# HS_I2C3 register map
Vendor: Texas Instruments
Peripheral module from a debugger description file (folder omap36xx).
Registers are 16-bit, read-write, reset 0x0 unless marked. A register's access mark holds for its fields unless they carry their own. Offsets are as the file gives them; lines under a group give offsets from that group; [hi:lo] are bit positions; {n}, {i} and the like mark numbered series; 'fields as' and 'values as' point back to an identical list; <NAME> marks a mode.

## HS_I2C3
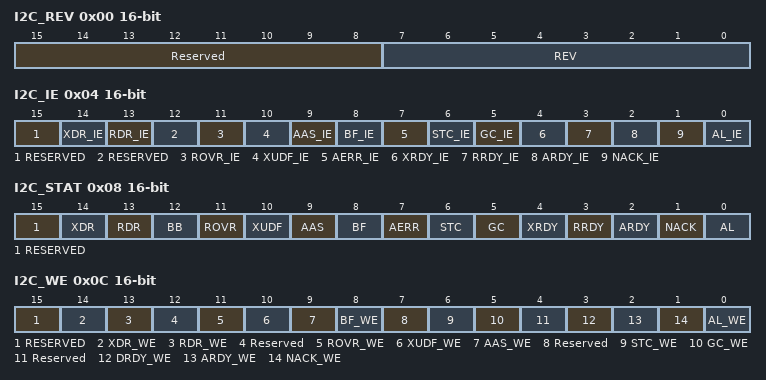
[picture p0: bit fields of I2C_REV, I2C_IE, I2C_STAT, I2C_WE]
0x00 I2C_REV ro (reset mask 0xFF00) — IP Revision Identifier (X.Y.R)Used by software to track features, bugs, and compatibility
  [15:8] Reserved — Read returns 0.
  [7:0] REV — IP revision[7:4] Major revision[3:0] Minor revisionExamples: 0x30 for 3.0, 0x31 for 3.1
0x04 I2C_IE — I2C interrupt enable register. This register contains the interrupt enable bits.
  [15] RESERVED — Write 0s for future compatibility. Read returns 0.
  [14] XDR_IE — Transmit Draining interrupt enable. Mask or unmask the interrupt signaled by the bit inI2C_STAT[XDR].
    0=Transmit Draining interrupt disabled; 1=Transmit Draining interrupt enabled
  [13] RDR_IE — Receive Draining interrupt enable. Mask or unmask the interrupt signaled by the bit inI2C_STAT[RDR].
    0=Receive Draining interrupt disabled; 1=Receive Draining interrupt enabled
  [12] RESERVED — Write 0s for future compatibility. Read returns 0.
  [11] ROVR_IE — Receive overrun enable set.
    0=Receive overrun interrupt disabled; 1=Receive Draining interrupt enabled
  [10] XUDF_IE — Transmit underflow enable set.
    0=Transmit underflow interrupt disabled; 1=Transmit underflow interrupt enabled
  [9] AAS_IE — Addressed as Slave interrupt enable. Mask or unmask the interrupt signaled by the bit inI2C_STAT[AAS].
    0=Addressed as Slave interrupt disabled; 1=Addressed as Slave interrupt enabled
  [8] BF_IE — Bus Free interrupt enable. Mask or unmask the interrupt signaled by the bit inI2C_STAT[BF].
    0=Bus Free interrupt disabled; 1=Bus Free interrupt enabled
  [7] AERR_IE — Access Error interrupt enable. Mask or unmask the interrupt signaled by the bit inI2C_STAT[AERR].
    0=Access Error interrupt disabled; 1=Access Error interrupt enabled
  [6] STC_IE — Start Condition interrupt enable. Mask or unmask the interrupt signaled by the bit inI2C_STAT[STC].
    0=Start Condition interrupt disabled; 1=Start Condition interrupt enabled
  [5] GC_IE — General Call interrupt enable. Mask or unmask the interrupt signaled by the bit inI2C_STAT[GC].
    0=General Call interrupt disabled; 1=General Call interrupt enabled
  [4] XRDY_IE — Transmit data ready interrupt enable. Mask or unmask the interrupt signaled by bit inI2C_STAT[XRDY]
    0=Transmit Data Ready interrupt disabled; 1=Transmit Data Ready interrupt enabled
  [3] RRDY_IE — Receive Data Ready interrupt enable. Mask or unmask the interrupt signaled by the bit inI2C_STAT[RRDY].
    0=Receive Data Ready interrupt disabled; 1=Receive Data Ready interrupt enabled
  [2] ARDY_IE — Register Access Ready interrupt enable. Mask or unmask the interrupt signaled by the bit inI2C_STAT[ARDY].
    0=Register Access Ready interrupt disabled; 1=Register Access Ready interrupt enabled
  [1] NACK_IE — No Acknowledgment interrupt enable. Mask or unmask the interrupt signaled by the bit inI2C_STAT[NACK].
    0=No Acknowledge interrupt disabled; 1=No Acknowledge Ready interrupt enabled
  [0] AL_IE — Arbitration Lost interrupt enable. Mask or unmask the interrupt signaled by the bit inI2C_STAT[AL].
    0=Arbitration Lost interrupt disabled; 1=Arbitration Lost interrupt enabled
0x08 I2C_STAT access per field — I2C status register. This register provides specific status information about the module, including interrupt status information
  [15] RESERVED rw — Write 0s for future compatibility. Read returns 0.
  [14] XDR rw — Transmit Draining IRQ status
    0=XDR_0_r (Transmit draining inactive); 1=XDR_1_r (Transmit draining active); 0=XDR_0_w (No effect); 1=XDR_1_w (Clear this bit to 0)
  [13] RDR rw — Receive Draining IRQ status
    0=RDR_0_r (Receive draining inactive); 1=RDR_1_r (Receive draining active); 0=RDR_0_w (No effect); 1=RDR_1_w (Clear this bit to 0)
  [12] BB ro — Bus busy status. Read-only bit. Writing this bit does not affect the read value.
    0=BB_0_r (Bus is free.); 1=BB_1_r (Bus is occupied.)
  [11] ROVR rw — Receive overrun status. Read-only bit. Writing this bit does not affect the read value.
    0=ROVR_0_r (Normal operation); 1=ROVR_1_r (Receiver overrun); 0=ROVR_0_w (No effect); 1=ROVR_1_w (Clear this bit to 0)
  [10] XUDF rw — Transmit underflow status. Read-only bit. Writing this bit does not affect the read value.
    0=XUDF_0_r (Normal operation); 1=XUDF_1_r (Transmit underflow); 0=XUDF_0_w (No effect); 1=XUDF_1_w (Clear this bit to 0)
  [9] AAS rw — Address recognized as slave IRQ status
    0=AAS_0_r (No action); 1=AAS_1_r (Address recognized); 0=AAS_0_w (No effect); 1=AAS_1_w (Clear this bit to 0.)
  [8] BF rw — Bus Free IRQ status
    0=BF_0_r (No action); 1=BF_1_r (Bus free); 0=BF_0_w (No effect); 1=BF_1_w (Clear this bit to 0.)
  [7] AERR rw — Access Error IRQ status
    0=AERR_0_r (No action); 1=AERR_1_r (Access error); 0=AERR_0_w (No effect); 1=AERR_1_w (Clear this bit to 0.)
  [6] STC rw — Start Condition IRQ status
    0=STC_0_r (No action); 1=STC_1_r (Start condition detected); 0=STC_0_w (No effect); 1=STC_1_w (Clear this bit to 0.)
  [5] GC rw — General Call IRQ status. Set to 1 when general call address detected. Interrupt signaled to MPU subsystem
    0=GC_0_r (No general call detected); 1=GC_1_r (General call address detected); 0=GC_0_w (No effect); 1=GC_1_w (Clear this bit to 0.)
  [4] XRDY rw — Transmit Data Ready IRQ status. Set to 1 in transmit mode when new data is requested for transmission. When this bit is set to 1, an interrupt is signaled to MPU subsystem
    0=XRDY_0_r (No transmit data is requested for transmission); 1=XRDY_1_r (Transmit data is requested for transmission); 0=XRDY_0_w (No effect); 1=XRDY_1_w (Clear this bit to 0.)
  [3] RRDY rw — Receive Data Ready IRQ status. Set to 1 when in receive mode, causing new data to be able to be read. When this bit is set to 1, an interrupt is signaled to MPU subsystem.
    0=RRDY_0_r (No data available); 1=RRDY_1_r (Receive data available); 0=RRDY_0_w (No effect); 1=RRDY_1_w (Clear this bit to 0.)
  [2] ARDY rw — Register Access Ready IRQ status. Setting this bit to 1 indicates that previous access has been performed and registers are ready to be accessed again. An interrupt is signaled to MPU subsystem.
    0=ARDY_0_r (Module busy); 1=ARDY_1_r (Access ready); 0=ARDY_0_w (No effect); 1=ARDY_1_w (Clear this bit to 0.)
  [1] NACK rw — No Acknowledgment IRQ status. This bit is set when No Acknowledgment has been received. An interrupt is signaled to MPU subsystem.In master mode, the transfer is automatically ended by generating a stop condition on the bus. The I2Ci.I2C_CON[1] STP, I2Ci.I2C_CON[10] MST and I2Ci.I2C_CON[9] TRX bits are automatically cleared to 0 (slave receiver mode). TX and RX FIFOs must be cleared (I2Ci.I2C_BUF[6] TXFIFO_CLR and I2Ci.I2C_BUF[14] RXFIFO_CLR bits set to 1).
    0=NACK_0_r (Normal operation); 1=NACK_1_r (No Acknowledge detected); 0=NACK_0_w (No effect); 1=NACK_1_w (Clear this bit to 0.)
  [0] AL rw — Arbitration Lost IRQ status. This bit is set automatically by the hardware when the I2C controller inside the device loses arbitration in master transmit mode. An interrupt is signaled to MPU subsystem.
    0=AL_0_r (Normal operation); 1=AL_1_r (Arbitration loss detected); 0=AL_0_w (No effect); 1=AL_1_w (Clear this bit to 0.)
0x0C I2C_WE — This register contains the wakeup enable bits.
  [15] RESERVED — Write 0s for future compatibility. Read returns 0.
  [14] XDR_WE — Transmit draining wakeup enable
    0=Transmit draining wakeup disabled; 1=Transmit draining wakeup enabled
  [13] RDR_WE — Receive draining wakeup enable
    0=Receive draining wakeup disabled; 1=Receive draining wakeup enabled
  [12] Reserved — Write 0s for future compatibility. Read returns 0.
  [11] ROVR_WE — Receive overrun wakeup set.
    0=Receive overrun wakeup disabled; 1=Receive overrun wakeup enabled
  [10] XUDF_WE — Transmit underflow wakeup set
    0=Transmit underflow wakeup disabled; 1=Transmit underflow wakeup enabled
  [9] AAS_WE — Address as slave wakeup enabled
    0=Address as slave wakeup disabled; 1=Address as slave wakeup enabled
  [8] BF_WE — Bus Free wakeup enable
    0=Bus Free wakeup disabled; 1=Bus Free wakeup enabled
  [7] Reserved — Write 0s for future compatibility. Read returns 0.
  [6] STC_WE — Start Condition wakeup enable
    0=Start condition wakeup disabled; 1=Start condition wakeup enabled
  [5] GC_WE — General call wakeup enable
    0=General call wakeup disabled; 1=General call wakeup enabled
  [4] Reserved — Write 0s for future compatibility. Read returns 0.
  [3] DRDY_WE — Transmit/receive data ready wakeup enable. Mask or unmask the interrupt signaled by bit inI2C_STAT[RRDY]
    0=Transmit/receive data ready wakeup disabled; 1=Transmit/receive data ready wakeup enabled
  [2] ARDY_WE — Register access ready wakeup enable
    0=Register access ready wakeup disabled; 1=Register access ready wakeup enabled
  [1] NACK_WE — No Acknowledgment wakeup enable
    0=No Acknowledgment wakeup disabled; 1=No Acknowledgment wakeup enabled
  [0] AL_WE — Arbitration lost wakeup enable
    0=Arbitration lost wakeup disabled; 1=Arbitration lost wakeup enabled
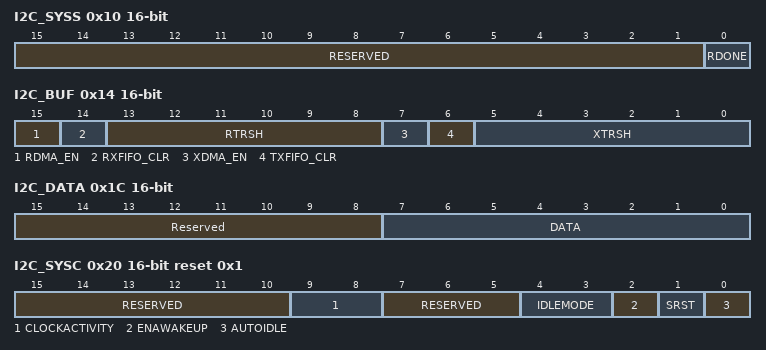
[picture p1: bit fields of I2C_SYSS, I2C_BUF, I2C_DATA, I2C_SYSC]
0x10 I2C_SYSS ro — This register provides status information about the module, excluding the interrupt status information.
  [15:1] RESERVED — Read returns 0.
  [0] RDONE — Internal reset monitoring
    0=RDONE_0_r (Internal module reset in ongoing); 1=RDONE_1_r (Internal module reset complete)
0x14 I2C_BUF — Receive DMA channel disabled.
  [15] RDMA_EN — Receive DMA channel enable
    0=Receive DMA channel disabled; 1=Receive DMA channel enabled
  [14] RXFIFO_CLR — Receive FIFO clear
    0=Normal mode; 1=Rx FIFO is reset
  [13:8] RTRSH — Threshold value for FIFO buffer in RX mode is equal to RTRSH + 1.
  [7] XDMA_EN — Transmit DMA channel enable
    0=Transmit DMA channel disabled; 1=Transmit DMA channel enabled
  [6] TXFIFO_CLR — Transmit FIFO clear
    0=Normal mode; 1=Tx FIFO is reset
  [5:0] XTRSH — Threshold value for FIFO buffer in TX mode is equal to XTRSH + 1.
0x18 I2C_CNT — This read/write register is used to control the numbers of bytes in the I2C data payload.
  [15:0] DCOUNT — Data count Because the transfer length for DCOUNT=0x0000 is 65536, the module does not allow the initiation of zero-data-byte transfers..
0x1C I2C_DATA (reset mask 0xFF00) — This register is the end point/entry point for the LH to read data from or write data to the FIFO buffer.
  [15:8] Reserved — Write 0s for future compatibility. Read returns 0.
  [7:0] DATA — Transmit/Receive FIFO data
0x20 I2C_SYSC access not given reset 0x1 — This register controls the various parameters of the L4-Core interconnect interface.
  [15:10] RESERVED rw — Write 0s for future compatibility. Read returns 0.
  [9:8] CLOCKACTIVITY rw — Clock Activity selection bits
    0=Both clocks can be cut off; 1=Only interface clock must be kept active; functional clock can be cut off; 2=Only functional clock must be kept active; interface clock can be cut off; 3=Both clocks must be kept active
  [7:5] RESERVED rw — Write 0s for future compatibility. Read returns 0.
  [4:3] IDLEMODE rw — Idle Mode selection bits
    0=Force Idle mode; 1=No Idle mode; 2=Smart Idle mode
  [2] ENAWAKEUP rw — Enable wakeup control bit
    0=Wakeup mechanism is disabled; 1=Wakeup mechanism is enabled
  [1] SRST — Software reset. This bit is automatically reset by the hardware. During reads, it always returns 0. (access RWl)
    0=Normal mode; 1=The module is reset
  [0] AUTOIDLE rw — Auto Idle enable control bit
    0=Auto Idle mechanism is disabled; 1=Auto Idle mechanism is enabled
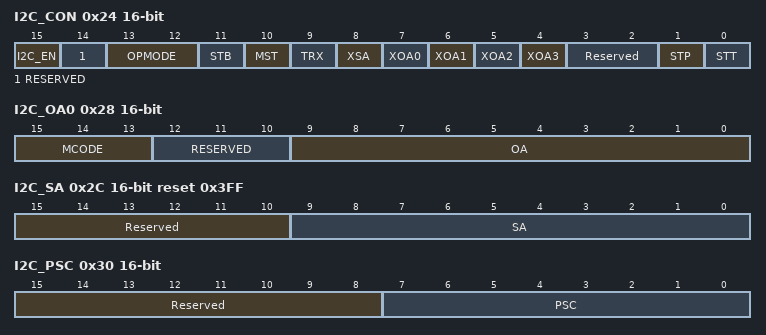
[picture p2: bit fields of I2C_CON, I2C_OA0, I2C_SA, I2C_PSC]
0x24 I2C_CON access not given — This register controls the functional features. Caution: during an active transfer phase (STT has been set to 1), no modification must be done in this register. Changing it may result in unpredictable behavior.
  [15] I2C_EN rw — Module enable bit
    0=Controller in reset. FIFO are cleared and status bits are set to their default value.; 1=Module enabled
  [14] RESERVED rw — Write 0s for future compatibility. Read returns 0.
  [13:12] OPMODE rw — Operation mode selection
    0=I2C Fast/Standard mode; 1=I2C High Speed mode; 2=SCCB mode
  [11] STB rw — Start byte mode (master mode only)
    0=Normal mode; 1=Start byte mode
  [10] MST — Master/slave mode selection (access RWl)
    0=Slave mode; 1=Master mode
  [9] TRX rw — Transmitter/Receiver mode (master mode only)
    0=Receiver mode; 1=Transmitter mode
  [8] XSA rw — Expand slave address enable bit
    0=7-bit address mode; 1=10-bit address mode
  [7] XOA0 rw — Expand Own Address 0 enable bit (default)
    0=7-bit address mode; 1=10-bit address mode
  [6] XOA1 rw — Expand Own Address 1 enable bit
    0=7-bit address mode; 1=10-bit address mode
  [5] XOA2 rw — Expand Own Address 2 enable bit
    0=7-bit address mode; 1=10-bit address mode
  [4] XOA3 rw — Expand Own Address 3 enable bit
    0=7-bit address mode; 1=10-bit address mode
  [3:2] Reserved rw — Write 0s for future compatibility. Read returns 0
  [1] STP rw — Stop condition (master mode only). The STP bit is cleared by the module itself once it has generated and detected the programmed stop condition on the bus.
    0=No action or generated stop (P) condition detected on the bus (by the module); 1=Stop condition queried
  [0] STT rw — Start condition (master mode only). The STT bit is cleared by the module itself once it has generated and detected the programmed start condition on the bus.
    0=No action or generated start (S) condition detected (by the module); 1=Start condition queried
0x28 I2C_OA0 — This register is used to specify the module I2C 7-bit or 10-bit address for the I2C operations or the 8-bit subaddress of the SCCB module register for the SCCB operations.
  [15:13] MCODE — Master Code value
  [12:10] RESERVED — Write 0s for future compatibility. Read returns 0.
  [9:0] OA — Own address 0 value
0x2C I2C_SA reset 0x3FF — This register is used to specify the addressed I2C module 7-bit or 10-bit address for the I2C operations or the 7-bit address of the external SCCB module for the SCCB operations.
  [15:10] Reserved — Write 0s for future compatibility. Read returns 0.
  [9:0] SA — Slave address value.
0x30 I2C_PSC — This register is used to specify the internal clocking of the I2C peripheral core. The core logic is sampled at the clock rate of the functional clock for the module divided by (PSC+1).
  [15:8] Reserved — Write 0s for future compatibility. Read returns 0.
  [7:0] PSC — Fast/Standard and SCCB modes prescale sampling clock divider value0x0: Divide by 10x1: Divide by 2.............................. 0xFF: Divide by 256
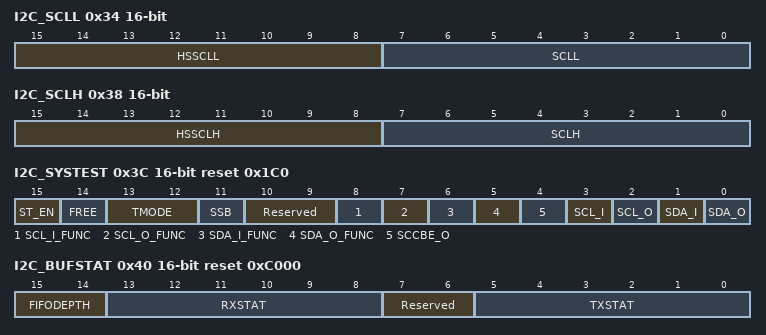
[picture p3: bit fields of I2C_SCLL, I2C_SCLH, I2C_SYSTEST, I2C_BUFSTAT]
0x34 I2C_SCLL — This register is used to determine the SCL low time value when master.
  [15:8] HSSCLL — IC High Speed mode SCL low time value.
  [7:0] SCLL — IC Fast/Standard or SCCB modes SCL low time value
0x38 I2C_SCLH — This register is used to determine the SCL low time value when master.
  [15:8] HSSCLH — IC high-speed mode SCL high time value
  [7:0] SCLH — IC Fast/Standard or SCCB modes SCL high time value
0x3C I2C_SYSTEST access per field reset 0x1C0 — This register is used to facilitate system-level tests by overriding some of the standard functional features of the peripheral.
  [15] ST_EN rw — System test enable
    0=Normal mode; 1=System test enabled. Permit other system test registers bits to be set
  [14] FREE rw — Free-running mode
    0=Stop mode (on breakpoint condition). If Master mode, it stops after completion of the ongoing bit transfer. In slave mode, it stops during the phase transfer when 1 byte is completely transmitted/received.; 1=Free-running mode
  [13:12] TMODE rw — Test mode select
    0=Functional mode (default); 2=Test of SCL counters (SCLL, SCLH, PSC). SCL provides a permanent clock with master mode.; 3=Loop back mode select + SDA/SCL IO mode select
  [11] SSB rw — Set status bits
    0=No action; 1=Set all interrupt status bits to 1
  [10:9] Reserved rw — Write 0s for future compatibility. Read returns 0.
  [8] SCL_I_FUNC ro — SCL line input value (functional mode).
    0=Read 0 from SCL line; 1=Read 1 from SCL line
  [7] SCL_O_FUNC ro — SCL line output value (functional mode).
    0=Driven 0 on SCL line; 1=Driven 1 on SCL line
  [6] SDA_I_FUNC ro — SDA line input value (functional mode).
    0=Read 0 from SDA line; 1=Read 1 from SDA line
  [5] SDA_O_FUNC rw — SDA line output value (functional mode).
    0=Driven 0 to SDA line; 1=Driven 1 to SDA line
  [4] SCCBE_O rw — SCCBE line sense output value. Writing is possible only if ST_EN bit is set to 1
    0=Write 0 to SCCBE line; 1=Write 1 to SCCBE line
  [3] SCL_I ro — SCL line sense input value
    0=Read 0 from SCL line; 1=Read 1 from SCL line
  [2] SCL_O rw — SCL line drive output value. Writing is possible only if ST_EN bit is set to 1
    0=Write 0 to SCL line; 1=Write 1 to SCL line
  [1] SDA_I ro — SDA line sense input value
    0=Read 0 from SDA line; 1=Read 1 from SDA line
  [0] SDA_O rw — SDA line drive output value. Writing is possible only if ST_EN bit is set to 1
    0=Write 0 to SDA line; 1=Write 1 to SDA line
0x40 I2C_BUFSTAT ro reset 0xC000 — This register contains the FIFO status information.
  [15:14] FIFODEPTH — FIFO depth indication.
    0=FIFODEPTH_0_r (8-bytes FIFO); 1=FIFODEPTH_1_r (16-bytes FIFO); 2=FIFODEPTH_2_r (32-bytes FIFO); 3=FIFODEPTH_3_r (64-bytes FIFO)
  [13:8] RXSTAT — RX Buffer Status. It indicates the number of bytes to be read in the RX FIFO when theI2C_STAT[RDR] is asserted (set to 1). This indication is useful only in receiver mode when the draining feature is enabled.
  [7:6] Reserved — Write 0s for future compatibility. Read returns 0.
  [5:0] TXSTAT — TX Buffer Status. It indicates the number of bytes to be written in the TX FIFO when theI2C_STAT[XDR] is asserted (set to 1). This indication is useful only in transmitter mode when the draining feature is enabled.
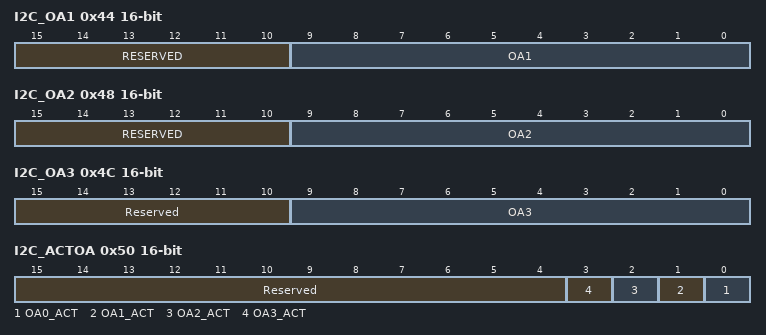
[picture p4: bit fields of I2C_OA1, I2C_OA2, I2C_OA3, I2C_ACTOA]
0x44 I2C_OA1 access per field — This register is used to specify the module I2C 7-bit or 10-bit address.
  [15:10] RESERVED ro — Write 0s for future compatibility. Read returns 0.
  [9:0] OA1 rw — Own address 1 value
0x48 I2C_OA2 access per field — This register is used to specify the module I2C 7-bit or 10-bit address.
  [15:10] RESERVED ro — Write 0s for future compatibility. Read returns 0.
  [9:0] OA2 rw — Own address 2 value
0x4C I2C_OA3 — This register is used to specify the module I2C 7-bit or 10-bit address.
  [15:10] Reserved — Write 0s for future compatibility. Read returns 0.
  [9:0] OA3 — Own address 3 value
0x50 I2C_ACTOA ro — This register contains the accessed slave Own Address indicators.
  [15:4] Reserved — Write 0s for future compatibility. Read returns 0.
  [n] OA{n}_ACT (n=0..3) — Own Address {n} active
    0=OA{n}_ACT_0_r (Own Address inactive); 1=OA{n}_ACT_1_r (Own Address active)
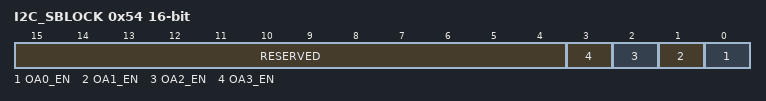
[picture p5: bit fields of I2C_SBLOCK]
0x54 I2C_SBLOCK access per field — This register controls the slave mode i2c bus clock features.
  [15:4] RESERVED ro — Write 0s for future compatibility. Read returns 0.
  [n] OA{n}_EN rw (n=0..3) — Enable I2C Clock Blocking for Own Address {n}
    0=I2C Clock Released; 1=I2C Clock Blocked
